AUTOSAR XML (schema 00044)
package /ComponentTypes
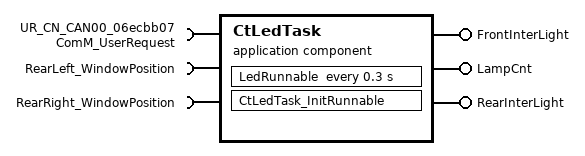
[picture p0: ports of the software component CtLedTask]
  application sw component type CtLedTask
    require port UR_CN_CAN00_06ecbb07: required-com-specs=[RequestComMode, GetCurrentComMode, GetMaxComMode, GetRequestedComMode], required-interface=ComM_UserRequest
    provide port FrontInterLight: nonqueued-sender-com-spec{data-element=bool_signal, init-value=0}, provided-interface=FrontInterLight
    provide port LampCnt: nonqueued-sender-com-spec{data-element=u8_Signal, init-value=0}, provided-interface=LampCnt
    provide port RearInterLight: nonqueued-sender-com-spec{data-element=Bool_Signal, init-value=0}, provided-interface=RearInterLight
    require port RearLeft_WindowPosition: nonqueued-receiver-com-spec{data-element=u8_signal, init-value=0}, required-interface=RearLeft_WindowPosition
    require port RearRight_WindowPosition: nonqueued-receiver-com-spec{data-element=u8_signal, init-value=0}, required-interface=RearRight_WindowPosition
    behavior CtLedTask_InternalBehavior
      timing event TMT_LedRunnable: start-on-event=LedRunnable, period=0.3
      init event CtLedTask_InitEvent: start-on-event=CtLedTask_InitRunnable
      runnable LedRunnable
        data-receive-point-by-arguments:
          access REC_RearLeft_WindowPosition_u8_signal: accessed-variable=RearLeft_WindowPosition.u8_signal
          access REC_RearRight_WindowPosition_u8_signal: accessed-variable=RearRight_WindowPosition.u8_signal
        data-send-points:
          access SEND_FrontInterLight_bool_signal: accessed-variable=FrontInterLight.bool_signal
          access SEND_LampCnt_u8_Signal: accessed-variable=LampCnt.u8_Signal
          access SEND_RearInterLight_Bool_Signal: accessed-variable=RearInterLight.Bool_Signal
      runnable CtLedTask_InitRunnable
        4 x sync call:
          SC_UR_CN_CAN00_06ecbb07_GetCurrentComMode: operation=UR_CN_CAN00_06ecbb07.GetCurrentComMode
          SC_UR_CN_CAN00_06ecbb07_GetMaxComMode: operation=UR_CN_CAN00_06ecbb07.GetMaxComMode
          SC_UR_CN_CAN00_06ecbb07_GetRequestedComMode: operation=UR_CN_CAN00_06ecbb07.GetRequestedComMode
          SC_UR_CN_CAN00_06ecbb07_RequestComMode: operation=UR_CN_CAN00_06ecbb07.RequestComMode
  swc implementation CtLedTask_Implementation: behavior=CtLedTask_InternalBehavior
